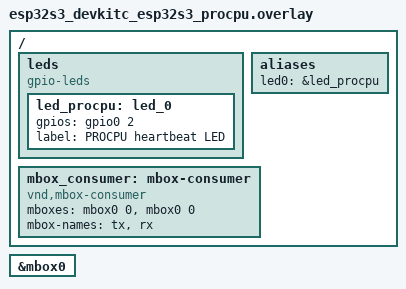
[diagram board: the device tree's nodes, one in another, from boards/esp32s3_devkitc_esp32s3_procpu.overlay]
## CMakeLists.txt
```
cmake_minimum_required(VERSION 3.20.0)

find_package(Zephyr REQUIRED HINTS $ENV{ZEPHYR_BASE})
project(03_shm_race_procpu)

target_sources(app PRIVATE src/main.c)
```

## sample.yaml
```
sample:
  name: 03_shm_race_lab
  description: >
    Lab 03 - Shared memory (ipmmem0 reuse) + MBOX doorbell notification.
    procpu writes an incrementing sequence number into the reused ipmmem0
    block and rings appcpu's MBOX doorbell every 200ms. appcpu drains that
    backlog more slowly (350ms) using an atomic pending-counter, so no
    doorbell is ever lost as a *count* - but the raw shared-memory value it
    reads back each time is only ever whatever is currently there, so
    intermediate values written in between are not guaranteed to survive.
    Confirmed on real hardware that reusing ipmmem0 for a NULL-payload
    mbox0 doorbell does not conflict with mbox0's own (unused when the
    payload is NULL) shared-memory scratch usage.

common:
  tags:
    - dual-core
    - ipc
    - mbox
    - shared-memory
  platform_allow:
    - esp32s3_devkitc/esp32s3/procpu

tests:
  sample.dual_core.shm_race:
    build_only: true
```

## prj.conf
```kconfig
# 03_SHM_RACE_LAB - core0 (procpu) image
#
# This lab's real teaching content: reusing the existing ipmmem0 shared
# SRAM block (already reserved by &ipm0/&mbox0 in the SoC devicetree) to
# pass a small struct directly between cores, with &mbox0 used purely as
# a signal-only "new data available" doorbell (see src/shared_mem.h and
# the doc for the full design and the race condition this lab reproduces).
#
# NOTE: &ipm0 is intentionally left DISABLED here - see 02_MBOX_DOORBELL_LAB's
# doc for why only one of ipm0/mbox0 is ever enabled per lab.

CONFIG_GPIO=y
CONFIG_MBOX=y

CONFIG_LOG=y
CONFIG_LOG_MODE_IMMEDIATE=y
```

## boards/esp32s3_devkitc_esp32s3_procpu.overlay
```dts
/*
 * Overlay for 03_SHM_RACE_LAB - core0 (procpu) image
 *
 * Reuses this series' GPIO2 "led0" heartbeat LED convention (see Lab 01).
 *
 * The "mbox-consumer" node is identical to 02_MBOX_DOORBELL_LAB's - see
 * that lab's doc for why this "vnd,mbox-consumer" binding is used and why
 * tx/rx both point at &mbox0 channel 0.
 *
 * NOTE: this lab does NOT add any new devicetree node for shared memory.
 * The 1KB block this lab writes its own struct into (ipmmem0, physical
 * address 0x3fce5000) is *already* declared in the SoC-level devicetree
 * as the private scratch buffer &ipm0/&mbox0 reserve for their own
 * message-copy mechanism (see the "shared-memory"/"shared-memory-size"
 * properties on those nodes). Because every mbox_send_dt() call in this
 * lab (like Lab 02) always passes a NULL payload, the mbox0 driver's own
 * memcpy into that buffer is never triggered - see src/shared_mem.h and
 * the doc for the full reasoning and the exact driver source checked to
 * confirm this.
 */

#include <zephyr/dt-bindings/gpio/gpio.h>

/ {
    leds {
        compatible = "gpio-leds";
        led_procpu: led_0 {
            gpios = <&gpio0 2 GPIO_ACTIVE_HIGH>;
            label = "PROCPU heartbeat LED";
        };
    };

    aliases {
        led0 = &led_procpu;
    };

    mbox_consumer: mbox-consumer {
        compatible = "vnd,mbox-consumer";
        mboxes = <&mbox0 0>, <&mbox0 0>;
        mbox-names = "tx", "rx";
    };
};

/*
 * &ipm0 stays disabled here on purpose - only &mbox0 is enabled, per this
 * series' policy (see 02_MBOX_DOORBELL_LAB's doc for the full reasoning).
 */
&mbox0 {
    status = "okay";
};
```

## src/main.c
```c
/*
 * main.c - 03_SHM_RACE_LAB (core0 / procpu image)
 *
 * Three independent things happen in this loop:
 *   1. Blinks its own heartbeat LED (GPIO2) every 500ms, same as Labs 01/02.
 *   2. Every SEND_PERIOD_MS, writes an incrementing sequence number into
 *      its half of the reused ipmmem0 block (see shared_mem.h) and rings
 *      appcpu's MBOX doorbell - a pure signal, no payload in the MBOX
 *      message itself (mbox_send_dt with NULL), exactly like Lab 02.
 *   3. Listens for appcpu's own doorbell replies (sent once per backlog
 *      item appcpu manages to process - see remote/src/main.c) and logs
 *      what appcpu actually saw, so "what I sent" vs "what appcpu actually
 *      received" can be directly compared on this core's serial console
 *      alone (appcpu has no console - see 01_HELLO_DUALCORE_LAB's doc).
 */

#include <zephyr/kernel.h>
#include <zephyr/drivers/gpio.h>
#include <zephyr/drivers/mbox.h>
#include <zephyr/sys/atomic.h>
#include <zephyr/logging/log.h>

#include "shared_mem.h"

LOG_MODULE_REGISTER(app_procpu, LOG_LEVEL_INF);

static const struct gpio_dt_spec led = GPIO_DT_SPEC_GET(DT_ALIAS(led0), gpios);

static const struct mbox_dt_spec tx_channel = MBOX_DT_SPEC_GET(DT_PATH(mbox_consumer), tx);
static const struct mbox_dt_spec rx_channel = MBOX_DT_SPEC_GET(DT_PATH(mbox_consumer), rx);

#define LED_PERIOD_MS  500
#define SEND_PERIOD_MS 200
#define POLL_PERIOD_MS 10

/*
 * Incremented from ISR context every time appcpu rings this core's
 * doorbell. Using atomic_t (instead of a plain bool/int) is exactly the
 * fix this lab is about: it guarantees that even if several doorbells
 * arrive back-to-back before the main loop gets around to draining them,
 * every single one is still counted - none of them get silently
 * overwritten the way a plain "new_reply = true;" flag could be.
 */
static atomic_t reply_pending = ATOMIC_INIT(0);

static void doorbell_from_appcpu(const struct device *dev, mbox_channel_id_t channel_id,
				  void *user_data, struct mbox_msg *data)
{
	ARG_UNUSED(dev);
	ARG_UNUSED(channel_id);
	ARG_UNUSED(user_data);
	ARG_UNUSED(data);

	atomic_inc(&reply_pending);
}

int main(void)
{
	LOG_INF("03_SHM_RACE_LAB (core0/procpu) starting");
	LOG_INF("reusing ipmmem0 at 0x%08x, size %u bytes (half=%u)",
		(unsigned int)SHM_BASE, (unsigned int)SHM_SIZE, (unsigned int)SHM_HALF_SIZE);

	if (!gpio_is_ready_dt(&led)) {
		LOG_ERR("led gpio not ready");
		return -1;
	}

	if (gpio_pin_configure_dt(&led, GPIO_OUTPUT_INACTIVE)) {
		LOG_ERR("failed to configure led");
		return -1;
	}

	mbox_register_callback_dt(&rx_channel, doorbell_from_appcpu, NULL);
	mbox_set_enabled_dt(&rx_channel, true);

	bool led_state = false;
	int64_t next_led_toggle = k_uptime_get() + LED_PERIOD_MS;
	int64_t next_send = k_uptime_get() + SEND_PERIOD_MS;
	uint32_t total_sent = 0;

	volatile struct p2a_payload *p2a = (volatile struct p2a_payload *)SHM_P2A_ADDR;
	volatile struct a2p_payload *a2p = (volatile struct a2p_payload *)SHM_A2P_ADDR;

	while (1) {
		int64_t now = k_uptime_get();

		if (now >= next_led_toggle) {
			led_state = !led_state;
			gpio_pin_set_dt(&led, led_state);
			next_led_toggle = now + LED_PERIOD_MS;
		}

		if (now >= next_send) {
			total_sent++;
			p2a->seq = total_sent;

			int ret = mbox_send_dt(&tx_channel, NULL);

			if (ret < 0) {
				LOG_ERR("mbox_send_dt failed (%d)", ret);
			} else {
				LOG_INF("sent seq=%u (total_sent=%u)", total_sent, total_sent);
			}

			next_send = now + SEND_PERIOD_MS;
		}

		while (atomic_get(&reply_pending) > 0) {
			atomic_dec(&reply_pending);

			uint32_t drained_count = a2p->drained_count;
			uint32_t last_seen_seq = a2p->last_seen_seq;

			LOG_INF("appcpu reply: drained_count=%u last_seen_seq=%u "
				"(procpu total_sent=%u, backlog=%u)",
				drained_count, last_seen_seq, total_sent,
				total_sent - drained_count);
		}

		k_msleep(POLL_PERIOD_MS);
	}

	return 0;
}
```
